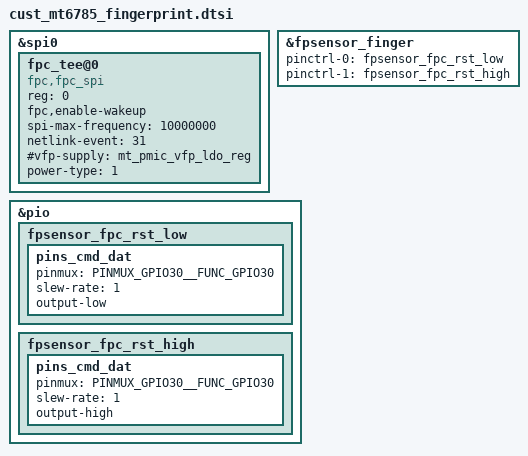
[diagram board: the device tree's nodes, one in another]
/*
 * Copyright (c) 2019 MediaTek Inc.
 * Copyright (C) 2021 XiaoMi, Inc.
 *
 * This program is free software; you can redistribute it and/or modify
 * it under the terms of the GNU General Public License version 2 as
 * published by the Free Software Foundation.
 *
 * This program is distributed in the hope that it will be useful,
 * but WITHOUT ANY WARRANTY; without even the implied warranty of
 * MERCHANTABILITY or FITNESS FOR A PARTICULAR PURPOSE.  See the
 * GNU General Public License for more details.
 */
&spi0 {
	fpc_tee@0 {
		compatible = "fpc,fpc_spi";
		reg = <0>;
		fpc,enable-wakeup;
		spi-max-frequency = <10000000>;
		netlink-event = <31>;
		#vfp-supply = <&mt_pmic_vfp_ldo_reg>;
		power-type = <1>;
		status = "okay";
	};

};

&fpsensor_finger {
	pinctrl-names =  "fpsensor_fpc_rst_low", "fpsensor_fpc_rst_high";
	pinctrl-0 = <&fpsensor_fpc_rst_low>;
	pinctrl-1 = <&fpsensor_fpc_rst_high>;
	status = "okay";
};

&pio {
	fpsensor_fpc_rst_low: fpsensor_fpc_rst_low {
		pins_cmd_dat {
			pinmux = <PINMUX_GPIO30__FUNC_GPIO30>;
			slew-rate = <1>;
			output-low;
		};
	};

	fpsensor_fpc_rst_high: fpsensor_fpc_rst_high {
		pins_cmd_dat {
			pinmux = <PINMUX_GPIO30__FUNC_GPIO30>;
			slew-rate = <1>;
			output-high;
		};
	};
};

